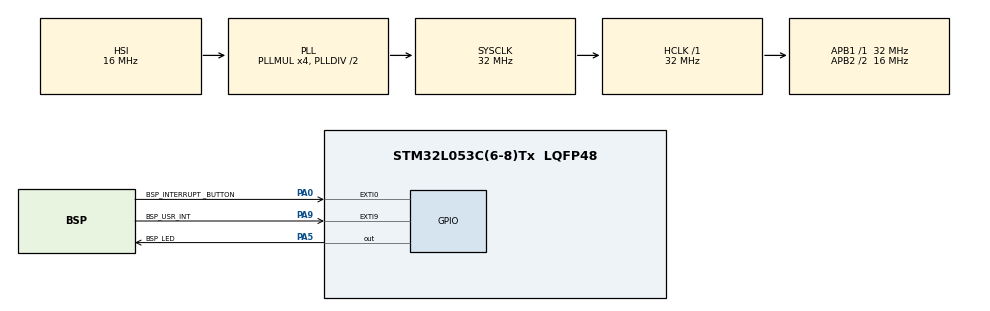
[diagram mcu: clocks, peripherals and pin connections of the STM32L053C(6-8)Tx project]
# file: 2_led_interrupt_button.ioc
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Mcu.Family=STM32L0
Mcu.Name=STM32L053C(6-8)Tx
Mcu.Package=LQFP48
NVIC.EXTI0_1_IRQn=true\:0\:0\:false\:false\:true\:true\:true\:true
PA0.GPIO_Label=BSP_INTERRUPT _BUTTON
PA0.GPIO_ModeDefaultEXTI=GPIO_MODE_IT_FALLING
PA0.GPIO_PuPd=GPIO_PULLUP
PA0.Signal=GPXTI0
PA5.GPIO_Label=BSP_LED
PA5.Signal=GPIO_Output
PA9.GPIO_Label=BSP_USR_INT
PA9.Signal=GPXTI9
ProjectManager.HeapSize=0x200
ProjectManager.StackSize=0x400
ProjectManager.TargetToolchain=STM32CubeIDE
RCC.AHBFreq_Value=32000000
RCC.APB1Freq_Value=32000000
RCC.APB1TimFreq_Value=32000000
RCC.APB2CLKDivider=RCC_HCLK_DIV2
RCC.APB2Freq_Value=16000000
RCC.APB2TimFreq_Value=32000000
RCC.HCLKFreq_Value=32000000
RCC.HSE_VALUE=8000000
RCC.HSI16_VALUE=16000000
RCC.HSI48MClockSelection=RCC_USBCLKSOURCE_HSI48
RCC.HSI48_VALUE=48000000
RCC.HSI_VALUE=16000000
RCC.LSE_VALUE=32768
RCC.MSI_VALUE=2097000
RCC.PLLMUL=RCC_PLLMUL_4
RCC.RTCClockSelectionVirtual=RCC_RTCCLKSOURCE_LSE
RCC.SYSCLKFreq_VALUE=32000000
RCC.SYSCLKSource=RCC_SYSCLKSOURCE_PLLCLK
RCC.VCOOutputFreq_Value=64000000
board=STM32L0538-DISCO

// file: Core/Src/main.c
/* USER CODE BEGIN Header */
/**
  ******************************************************************************
  * @file    main.c
  * @brief   Main program body
  ******************************************************************************
  * @attention
  *
  * Copyright (c) 2024 STMicroelectronics.
  * All rights reserved.
  *
  * This software is licensed under terms that can be found in the LICENSE file
  * in the root directory of this software component.
  * If no LICENSE file comes with this software, it is provided AS-IS.
  *
  ******************************************************************************
  */
/* USER CODE END Header */
#include "main.h"

/* USER CODE BEGIN PV */

volatile uint32_t button_pressed = 0; // Flag to indicate button press

/* USER CODE END PV */

void SystemClock_Config(void);
static void MX_GPIO_Init(void);

int main(void)
{

  /* MCU Configuration--------------------------------------------------------*/

  /* Reset of all peripherals, Initializes the Flash interface and the Systick. */
  HAL_Init();

  /* Configure the system clock */
  SystemClock_Config();

  /* Initialize all configured peripherals */
  MX_GPIO_Init();

  /* Infinite loop */
  while (1)
  {

    /* USER CODE BEGIN 3 */
	  if (button_pressed)
	      {
	        HAL_GPIO_TogglePin(BSP_LED_GPIO_Port, BSP_LED_Pin); // Toggle LED state
	        button_pressed = 0; // Reset button press flag
	      }
  }
  /* USER CODE END 3 */
}

void SystemClock_Config(void)
{
  RCC_OscInitTypeDef RCC_OscInitStruct = {0};
  RCC_ClkInitTypeDef RCC_ClkInitStruct = {0};

  /** Configure the main internal regulator output voltage
  */
  __HAL_PWR_VOLTAGESCALING_CONFIG(PWR_REGULATOR_VOLTAGE_SCALE1);

  /** Initializes the RCC Oscillators according to the specified parameters
  * in the RCC_OscInitTypeDef structure.
  */
  RCC_OscInitStruct.OscillatorType = RCC_OSCILLATORTYPE_HSI;
  RCC_OscInitStruct.HSIState = RCC_HSI_ON;
  RCC_OscInitStruct.HSICalibrationValue = RCC_HSICALIBRATION_DEFAULT;
  RCC_OscInitStruct.PLL.PLLState = RCC_PLL_ON;
  RCC_OscInitStruct.PLL.PLLSource = RCC_PLLSOURCE_HSI;
  RCC_OscInitStruct.PLL.PLLMUL = RCC_PLLMUL_4;
  RCC_OscInitStruct.PLL.PLLDIV = RCC_PLLDIV_2;
  if (HAL_RCC_OscConfig(&RCC_OscInitStruct) != HAL_OK)
  {
    Error_Handler();
  }

  /** Initializes the CPU, AHB and APB buses clocks
  */
  RCC_ClkInitStruct.ClockType = RCC_CLOCKTYPE_HCLK|RCC_CLOCKTYPE_SYSCLK
                              |RCC_CLOCKTYPE_PCLK1|RCC_CLOCKTYPE_PCLK2;
  RCC_ClkInitStruct.SYSCLKSource = RCC_SYSCLKSOURCE_PLLCLK;
  RCC_ClkInitStruct.AHBCLKDivider = RCC_SYSCLK_DIV1;
  RCC_ClkInitStruct.APB1CLKDivider = RCC_HCLK_DIV1;
  RCC_ClkInitStruct.APB2CLKDivider = RCC_HCLK_DIV2;

  if (HAL_RCC_ClockConfig(&RCC_ClkInitStruct, FLASH_LATENCY_1) != HAL_OK)
  {
    Error_Handler();
  }
}

static void MX_GPIO_Init(void)
{
  GPIO_InitTypeDef GPIO_InitStruct = {0};

  /* GPIO Ports Clock Enable */
  __HAL_RCC_GPIOA_CLK_ENABLE();

  /*Configure GPIO pin Output Level */
  HAL_GPIO_WritePin(BSP_LED_GPIO_Port, BSP_LED_Pin, GPIO_PIN_RESET);

  /*Configure GPIO pin : BSP_INTERRUPT__BUTTON_Pin */
  GPIO_InitStruct.Pin = BSP_INTERRUPT__BUTTON_Pin;
  GPIO_InitStruct.Mode = GPIO_MODE_IT_FALLING;
  GPIO_InitStruct.Pull = GPIO_PULLUP;
  HAL_GPIO_Init(BSP_INTERRUPT__BUTTON_GPIO_Port, &GPIO_InitStruct);

  /*Configure GPIO pin : BSP_LED_Pin */
  GPIO_InitStruct.Pin = BSP_LED_Pin;
  GPIO_InitStruct.Mode = GPIO_MODE_OUTPUT_PP;
  GPIO_InitStruct.Pull = GPIO_NOPULL;
  GPIO_InitStruct.Speed = GPIO_SPEED_FREQ_LOW;
  HAL_GPIO_Init(BSP_LED_GPIO_Port, &GPIO_InitStruct);

  /*Configure GPIO pin : BSP_USR_INT_Pin */
  GPIO_InitStruct.Pin = BSP_USR_INT_Pin;
  GPIO_InitStruct.Mode = GPIO_MODE_IT_RISING;
  GPIO_InitStruct.Pull = GPIO_NOPULL;
  HAL_GPIO_Init(BSP_USR_INT_GPIO_Port, &GPIO_InitStruct);

  /* EXTI interrupt init*/
  HAL_NVIC_SetPriority(EXTI0_1_IRQn, 0, 0);
  HAL_NVIC_EnableIRQ(EXTI0_1_IRQn);

}

/* USER CODE BEGIN 4 */
void HAL_GPIO_EXTI_Callback(uint16_t GPIO_Pin)
{
  if (GPIO_Pin == BSP_INTERRUPT__BUTTON_Pin)
  {
    button_pressed = 1; // Set button press flag
  }
}
/* USER CODE END 4 */

void Error_Handler(void)
{
  __disable_irq();
  while (1)
  {
  }
}
